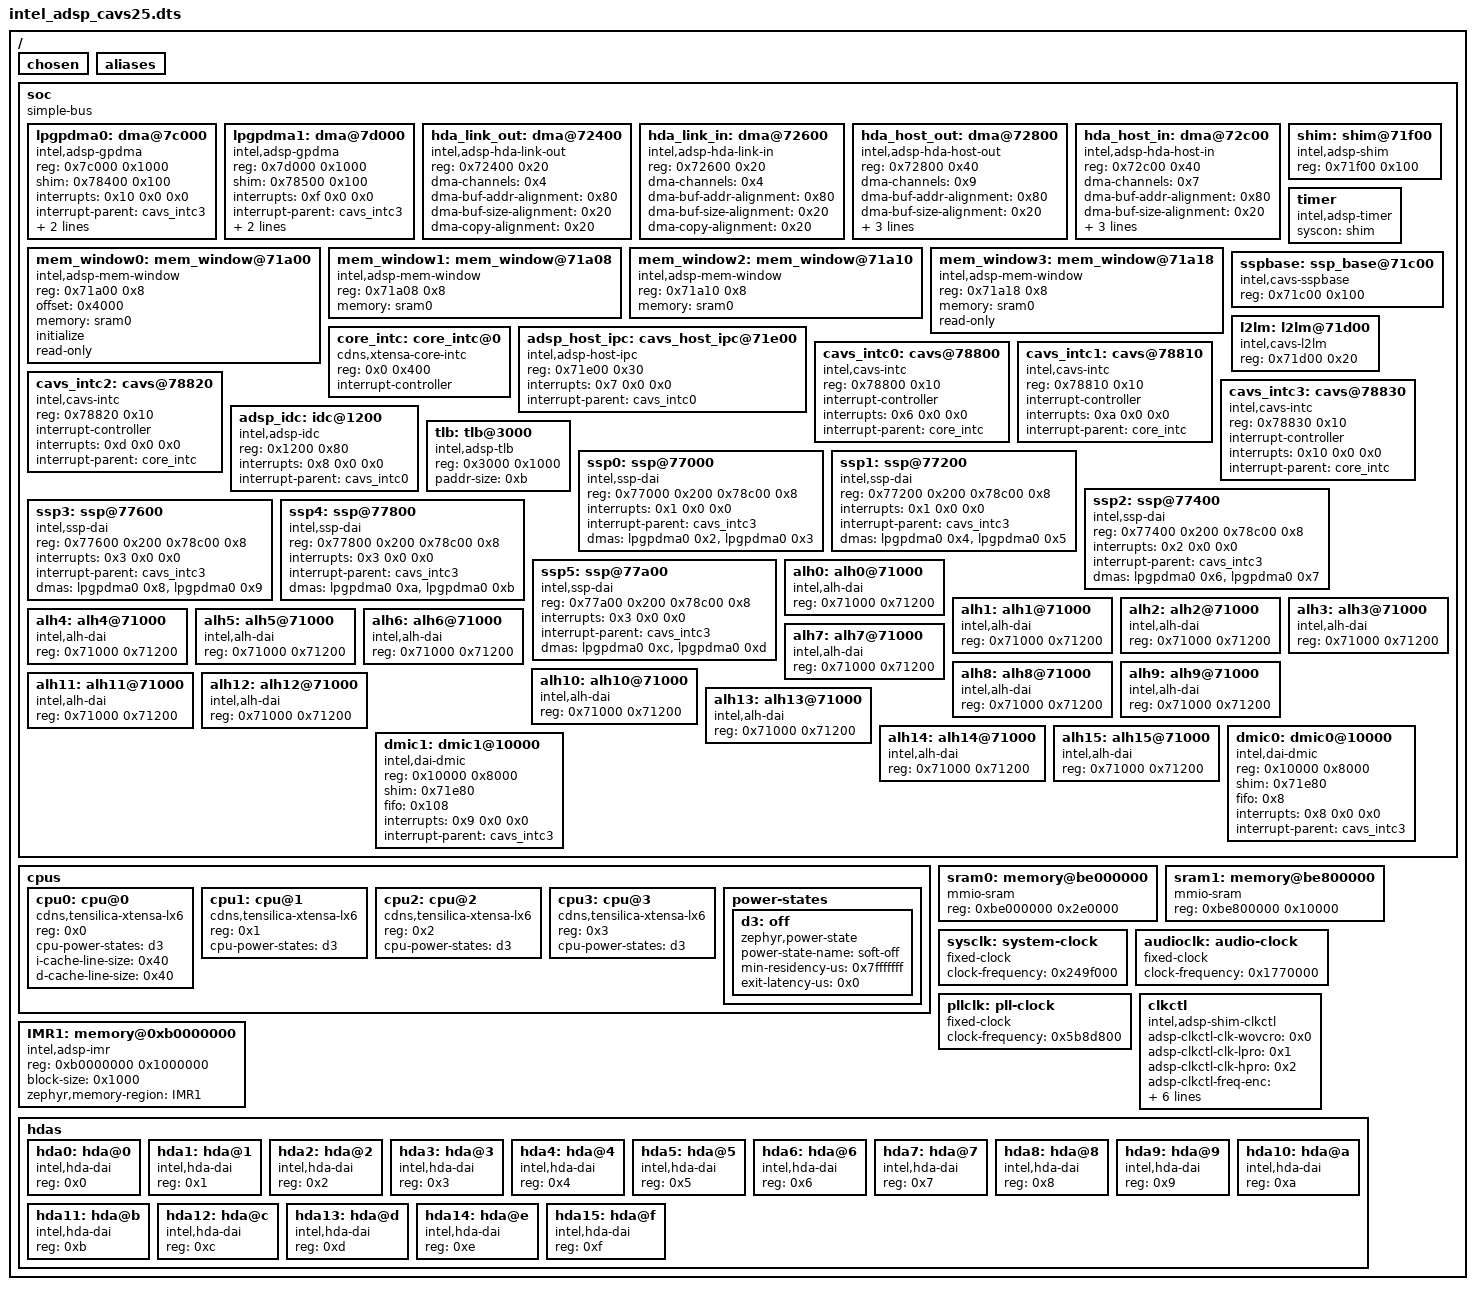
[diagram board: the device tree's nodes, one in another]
/dts-v1/;

/ {
	#address-cells = < 0x1 >;
	#size-cells = < 0x1 >;
	chosen {
	};
	aliases {
	};
	soc {
		#address-cells = < 0x1 >;
		#size-cells = < 0x1 >;
		compatible = "simple-bus";
		ranges;
		lpgpdma0: dma@7c000 {
			compatible = "intel,adsp-gpdma";
			#dma-cells = < 0x1 >;
			reg = < 0x7c000 0x1000 >;
			shim = < 0x78400 0x100 >;
			interrupts = < 0x10 0x0 0x0 >;
			interrupt-parent = < &cavs_intc3 >;
			dma-buf-size-alignment = < 0x4 >;
			dma-copy-alignment = < 0x4 >;
			status = "okay";
			phandle = < 0x7 >;
		};
		lpgpdma1: dma@7d000 {
			compatible = "intel,adsp-gpdma";
			#dma-cells = < 0x1 >;
			reg = < 0x7d000 0x1000 >;
			shim = < 0x78500 0x100 >;
			interrupts = < 0xf 0x0 0x0 >;
			interrupt-parent = < &cavs_intc3 >;
			dma-buf-size-alignment = < 0x4 >;
			dma-copy-alignment = < 0x4 >;
			status = "okay";
		};
		hda_link_out: dma@72400 {
			compatible = "intel,adsp-hda-link-out";
			#dma-cells = < 0x1 >;
			reg = < 0x72400 0x20 >;
			dma-channels = < 0x4 >;
			dma-buf-addr-alignment = < 0x80 >;
			dma-buf-size-alignment = < 0x20 >;
			dma-copy-alignment = < 0x20 >;
			status = "okay";
		};
		hda_link_in: dma@72600 {
			compatible = "intel,adsp-hda-link-in";
			#dma-cells = < 0x1 >;
			reg = < 0x72600 0x20 >;
			dma-channels = < 0x4 >;
			dma-buf-addr-alignment = < 0x80 >;
			dma-buf-size-alignment = < 0x20 >;
			dma-copy-alignment = < 0x20 >;
			status = "okay";
		};
		hda_host_out: dma@72800 {
			compatible = "intel,adsp-hda-host-out";
			#dma-cells = < 0x1 >;
			reg = < 0x72800 0x40 >;
			dma-channels = < 0x9 >;
			dma-buf-addr-alignment = < 0x80 >;
			dma-buf-size-alignment = < 0x20 >;
			dma-copy-alignment = < 0x20 >;
			interrupts = < 0x10 0x0 0x0 >;
			interrupt-parent = < &cavs_intc1 >;
			status = "okay";
		};
		hda_host_in: dma@72c00 {
			compatible = "intel,adsp-hda-host-in";
			#dma-cells = < 0x1 >;
			reg = < 0x72c00 0x40 >;
			dma-channels = < 0x7 >;
			dma-buf-addr-alignment = < 0x80 >;
			dma-buf-size-alignment = < 0x20 >;
			dma-copy-alignment = < 0x20 >;
			interrupts = < 0x0 0x0 0x0 >;
			interrupt-parent = < &cavs_intc1 >;
			status = "okay";
		};
		shim: shim@71f00 {
			compatible = "intel,adsp-shim";
			reg = < 0x71f00 0x100 >;
			phandle = < 0x4 >;
		};
		mem_window0: mem_window@71a00 {
			compatible = "intel,adsp-mem-window";
			reg = < 0x71a00 0x8 >;
			offset = < 0x4000 >;
			memory = < &sram0 >;
			initialize;
			read-only;
		};
		mem_window1: mem_window@71a08 {
			compatible = "intel,adsp-mem-window";
			reg = < 0x71a08 0x8 >;
			memory = < &sram0 >;
		};
		mem_window2: mem_window@71a10 {
			compatible = "intel,adsp-mem-window";
			reg = < 0x71a10 0x8 >;
			memory = < &sram0 >;
		};
		mem_window3: mem_window@71a18 {
			compatible = "intel,adsp-mem-window";
			reg = < 0x71a18 0x8 >;
			memory = < &sram0 >;
			read-only;
		};
		timer: timer {
			compatible = "intel,adsp-timer";
			syscon = < &shim >;
		};
		sspbase: ssp_base@71c00 {
			compatible = "intel,cavs-sspbase";
			reg = < 0x71c00 0x100 >;
		};
		l2lm: l2lm@71d00 {
			compatible = "intel,cavs-l2lm";
			reg = < 0x71d00 0x20 >;
		};
		core_intc: core_intc@0 {
			compatible = "cdns,xtensa-core-intc";
			reg = < 0x0 0x400 >;
			interrupt-controller;
			#interrupt-cells = < 0x3 >;
			phandle = < 0x6 >;
		};
		adsp_host_ipc: cavs_host_ipc@71e00 {
			compatible = "intel,adsp-host-ipc";
			reg = < 0x71e00 0x30 >;
			interrupts = < 0x7 0x0 0x0 >;
			interrupt-parent = < &cavs_intc0 >;
		};
		cavs_intc0: cavs@78800 {
			compatible = "intel,cavs-intc";
			reg = < 0x78800 0x10 >;
			interrupt-controller;
			#interrupt-cells = < 0x3 >;
			interrupts = < 0x6 0x0 0x0 >;
			interrupt-parent = < &core_intc >;
			phandle = < 0x5 >;
		};
		cavs_intc1: cavs@78810 {
			compatible = "intel,cavs-intc";
			reg = < 0x78810 0x10 >;
			interrupt-controller;
			#interrupt-cells = < 0x3 >;
			interrupts = < 0xa 0x0 0x0 >;
			interrupt-parent = < &core_intc >;
			phandle = < 0x2 >;
		};
		cavs_intc2: cavs@78820 {
			compatible = "intel,cavs-intc";
			reg = < 0x78820 0x10 >;
			interrupt-controller;
			#interrupt-cells = < 0x3 >;
			interrupts = < 0xd 0x0 0x0 >;
			interrupt-parent = < &core_intc >;
		};
		cavs_intc3: cavs@78830 {
			compatible = "intel,cavs-intc";
			reg = < 0x78830 0x10 >;
			interrupt-controller;
			#interrupt-cells = < 0x3 >;
			interrupts = < 0x10 0x0 0x0 >;
			interrupt-parent = < &core_intc >;
			phandle = < 0x1 >;
		};
		adsp_idc: idc@1200 {
			compatible = "intel,adsp-idc";
			reg = < 0x1200 0x80 >;
			interrupts = < 0x8 0x0 0x0 >;
			interrupt-parent = < &cavs_intc0 >;
		};
		tlb: tlb@3000 {
			compatible = "intel,adsp-tlb";
			reg = < 0x3000 0x1000 >;
			paddr-size = < 0xb >;
		};
		ssp0: ssp@77000 {
			compatible = "intel,ssp-dai";
			#address-cells = < 0x1 >;
			#size-cells = < 0x0 >;
			reg = < 0x77000 0x200 0x78c00 0x8 >;
			interrupts = < 0x1 0x0 0x0 >;
			interrupt-parent = < &cavs_intc3 >;
			dmas = < &lpgpdma0 0x2 &lpgpdma0 0x3 >;
			dma-names = "tx", "rx";
			status = "okay";
		};
		ssp1: ssp@77200 {
			compatible = "intel,ssp-dai";
			#address-cells = < 0x1 >;
			#size-cells = < 0x0 >;
			reg = < 0x77200 0x200 0x78c00 0x8 >;
			interrupts = < 0x1 0x0 0x0 >;
			interrupt-parent = < &cavs_intc3 >;
			dmas = < &lpgpdma0 0x4 &lpgpdma0 0x5 >;
			dma-names = "tx", "rx";
			status = "okay";
		};
		ssp2: ssp@77400 {
			compatible = "intel,ssp-dai";
			#address-cells = < 0x1 >;
			#size-cells = < 0x0 >;
			reg = < 0x77400 0x200 0x78c00 0x8 >;
			interrupts = < 0x2 0x0 0x0 >;
			interrupt-parent = < &cavs_intc3 >;
			dmas = < &lpgpdma0 0x6 &lpgpdma0 0x7 >;
			dma-names = "tx", "rx";
			status = "okay";
		};
		ssp3: ssp@77600 {
			compatible = "intel,ssp-dai";
			#address-cells = < 0x1 >;
			#size-cells = < 0x0 >;
			reg = < 0x77600 0x200 0x78c00 0x8 >;
			interrupts = < 0x3 0x0 0x0 >;
			interrupt-parent = < &cavs_intc3 >;
			dmas = < &lpgpdma0 0x8 &lpgpdma0 0x9 >;
			dma-names = "tx", "rx";
			status = "okay";
		};
		ssp4: ssp@77800 {
			compatible = "intel,ssp-dai";
			#address-cells = < 0x1 >;
			#size-cells = < 0x0 >;
			reg = < 0x77800 0x200 0x78c00 0x8 >;
			interrupts = < 0x3 0x0 0x0 >;
			interrupt-parent = < &cavs_intc3 >;
			dmas = < &lpgpdma0 0xa &lpgpdma0 0xb >;
			dma-names = "tx", "rx";
			status = "okay";
		};
		ssp5: ssp@77a00 {
			compatible = "intel,ssp-dai";
			#address-cells = < 0x1 >;
			#size-cells = < 0x0 >;
			reg = < 0x77a00 0x200 0x78c00 0x8 >;
			interrupts = < 0x3 0x0 0x0 >;
			interrupt-parent = < &cavs_intc3 >;
			dmas = < &lpgpdma0 0xc &lpgpdma0 0xd >;
			dma-names = "tx", "rx";
			status = "okay";
		};
		alh0: alh0@71000 {
			compatible = "intel,alh-dai";
			reg = < 0x71000 0x71200 >;
			status = "okay";
		};
		alh1: alh1@71000 {
			compatible = "intel,alh-dai";
			reg = < 0x71000 0x71200 >;
			status = "okay";
		};
		alh2: alh2@71000 {
			compatible = "intel,alh-dai";
			reg = < 0x71000 0x71200 >;
			status = "okay";
		};
		alh3: alh3@71000 {
			compatible = "intel,alh-dai";
			reg = < 0x71000 0x71200 >;
			status = "okay";
		};
		alh4: alh4@71000 {
			compatible = "intel,alh-dai";
			reg = < 0x71000 0x71200 >;
			status = "okay";
		};
		alh5: alh5@71000 {
			compatible = "intel,alh-dai";
			reg = < 0x71000 0x71200 >;
			status = "okay";
		};
		alh6: alh6@71000 {
			compatible = "intel,alh-dai";
			reg = < 0x71000 0x71200 >;
			status = "okay";
		};
		alh7: alh7@71000 {
			compatible = "intel,alh-dai";
			reg = < 0x71000 0x71200 >;
			status = "okay";
		};
		alh8: alh8@71000 {
			compatible = "intel,alh-dai";
			reg = < 0x71000 0x71200 >;
			status = "okay";
		};
		alh9: alh9@71000 {
			compatible = "intel,alh-dai";
			reg = < 0x71000 0x71200 >;
			status = "okay";
		};
		alh10: alh10@71000 {
			compatible = "intel,alh-dai";
			reg = < 0x71000 0x71200 >;
			status = "okay";
		};
		alh11: alh11@71000 {
			compatible = "intel,alh-dai";
			reg = < 0x71000 0x71200 >;
			status = "okay";
		};
		alh12: alh12@71000 {
			compatible = "intel,alh-dai";
			reg = < 0x71000 0x71200 >;
			status = "okay";
		};
		alh13: alh13@71000 {
			compatible = "intel,alh-dai";
			reg = < 0x71000 0x71200 >;
			status = "okay";
		};
		alh14: alh14@71000 {
			compatible = "intel,alh-dai";
			reg = < 0x71000 0x71200 >;
			status = "okay";
		};
		alh15: alh15@71000 {
			compatible = "intel,alh-dai";
			reg = < 0x71000 0x71200 >;
			status = "okay";
		};
		dmic0: dmic0@10000 {
			compatible = "intel,dai-dmic";
			reg = < 0x10000 0x8000 >;
			shim = < 0x71e80 >;
			fifo = < 0x8 >;
			interrupts = < 0x8 0x0 0x0 >;
			interrupt-parent = < &cavs_intc3 >;
		};
		dmic1: dmic1@10000 {
			compatible = "intel,dai-dmic";
			reg = < 0x10000 0x8000 >;
			shim = < 0x71e80 >;
			fifo = < 0x108 >;
			interrupts = < 0x9 0x0 0x0 >;
			interrupt-parent = < &cavs_intc3 >;
		};
	};
	cpus {
		#address-cells = < 0x1 >;
		#size-cells = < 0x0 >;
		cpu0: cpu@0 {
			device_type = "cpu";
			compatible = "cdns,tensilica-xtensa-lx6";
			reg = < 0x0 >;
			cpu-power-states = < &d3 >;
			i-cache-line-size = < 0x40 >;
			d-cache-line-size = < 0x40 >;
		};
		cpu1: cpu@1 {
			device_type = "cpu";
			compatible = "cdns,tensilica-xtensa-lx6";
			reg = < 0x1 >;
			cpu-power-states = < &d3 >;
		};
		cpu2: cpu@2 {
			device_type = "cpu";
			compatible = "cdns,tensilica-xtensa-lx6";
			reg = < 0x2 >;
			cpu-power-states = < &d3 >;
		};
		cpu3: cpu@3 {
			device_type = "cpu";
			compatible = "cdns,tensilica-xtensa-lx6";
			reg = < 0x3 >;
			cpu-power-states = < &d3 >;
		};
		power-states {
			d3: off {
				compatible = "zephyr,power-state";
				power-state-name = "soft-off";
				min-residency-us = < 0x7fffffff >;
				exit-latency-us = < 0x0 >;
				phandle = < 0x8 >;
			};
		};
	};
	sram0: memory@be000000 {
		device_type = "memory";
		compatible = "mmio-sram";
		reg = < 0xbe000000 0x2e0000 >;
		phandle = < 0x3 >;
	};
	sram1: memory@be800000 {
		device_type = "memory";
		compatible = "mmio-sram";
		reg = < 0xbe800000 0x10000 >;
	};
	sysclk: system-clock {
		compatible = "fixed-clock";
		clock-frequency = < 0x249f000 >;
		#clock-cells = < 0x0 >;
	};
	audioclk: audio-clock {
		compatible = "fixed-clock";
		clock-frequency = < 0x1770000 >;
		#clock-cells = < 0x0 >;
	};
	pllclk: pll-clock {
		compatible = "fixed-clock";
		clock-frequency = < 0x5b8d800 >;
		#clock-cells = < 0x0 >;
	};
	clkctl: clkctl {
		compatible = "intel,adsp-shim-clkctl";
		adsp-clkctl-clk-wovcro = < 0x0 >;
		adsp-clkctl-clk-lpro = < 0x1 >;
		adsp-clkctl-clk-hpro = < 0x2 >;
		adsp-clkctl-freq-enc = < 0x1a 0x20000002 0x80000002 >;
		adsp-clkctl-freq-mask = < 0x10 0x20000000 0x80000000 >;
		adsp-clkctl-freq-default = < 0x2 >;
		adsp-clkctl-freq-lowest = < 0x0 >;
		wovcro-supported;
	};
	IMR1: memory@0xb0000000 {
		compatible = "intel,adsp-imr";
		reg = < 0xb0000000 0x1000000 >;
		block-size = < 0x1000 >;
		zephyr,memory-region = "IMR1";
	};
	hdas {
		#address-cells = < 0x1 >;
		#size-cells = < 0x0 >;
		hda0: hda@0 {
			compatible = "intel,hda-dai";
			status = "okay";
			reg = < 0x0 >;
		};
		hda1: hda@1 {
			compatible = "intel,hda-dai";
			status = "okay";
			reg = < 0x1 >;
		};
		hda2: hda@2 {
			compatible = "intel,hda-dai";
			status = "okay";
			reg = < 0x2 >;
		};
		hda3: hda@3 {
			compatible = "intel,hda-dai";
			status = "okay";
			reg = < 0x3 >;
		};
		hda4: hda@4 {
			compatible = "intel,hda-dai";
			status = "okay";
			reg = < 0x4 >;
		};
		hda5: hda@5 {
			compatible = "intel,hda-dai";
			status = "okay";
			reg = < 0x5 >;
		};
		hda6: hda@6 {
			compatible = "intel,hda-dai";
			status = "okay";
			reg = < 0x6 >;
		};
		hda7: hda@7 {
			compatible = "intel,hda-dai";
			status = "okay";
			reg = < 0x7 >;
		};
		hda8: hda@8 {
			compatible = "intel,hda-dai";
			status = "okay";
			reg = < 0x8 >;
		};
		hda9: hda@9 {
			compatible = "intel,hda-dai";
			status = "okay";
			reg = < 0x9 >;
		};
		hda10: hda@a {
			compatible = "intel,hda-dai";
			status = "okay";
			reg = < 0xa >;
		};
		hda11: hda@b {
			compatible = "intel,hda-dai";
			status = "okay";
			reg = < 0xb >;
		};
		hda12: hda@c {
			compatible = "intel,hda-dai";
			status = "okay";
			reg = < 0xc >;
		};
		hda13: hda@d {
			compatible = "intel,hda-dai";
			status = "okay";
			reg = < 0xd >;
		};
		hda14: hda@e {
			compatible = "intel,hda-dai";
			status = "okay";
			reg = < 0xe >;
		};
		hda15: hda@f {
			compatible = "intel,hda-dai";
			status = "okay";
			reg = < 0xf >;
		};
	};
};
